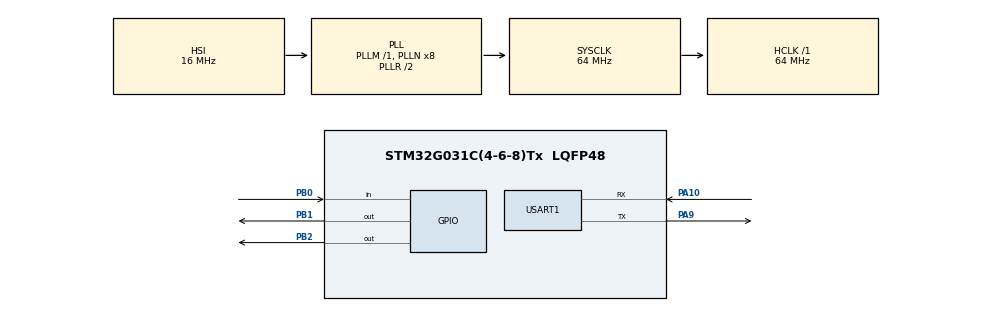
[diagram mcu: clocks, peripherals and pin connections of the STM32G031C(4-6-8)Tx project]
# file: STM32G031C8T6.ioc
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Mcu.Family=STM32G0
Mcu.Name=STM32G031C(4-6-8)Tx
Mcu.Package=LQFP48
PA10.Mode=Asynchronous
PA10.Signal=USART1_RX
PA13.Mode=Serial_Wire
PA13.Signal=SYS_SWDIO
PA14-BOOT0.Mode=Serial_Wire
PA14-BOOT0.Signal=SYS_SWCLK
PA9.Mode=Asynchronous
PA9.Signal=USART1_TX
PB0.Signal=GPIO_Input
PB1.GPIO_ModeDefaultOutputPP=GPIO_MODE_OUTPUT_PP
PB1.PinState=GPIO_PIN_RESET
PB1.Signal=GPIO_Output
PB2.PinState=GPIO_PIN_RESET
PB2.Signal=GPIO_Output
PF0-OSC_IN\ (PF0).Mode=HSE-External-Oscillator
PF0-OSC_IN\ (PF0).Signal=RCC_OSC_IN
PF1-OSC_OUT\ (PF1).Mode=HSE-External-Oscillator
PF1-OSC_OUT\ (PF1).Signal=RCC_OSC_OUT
ProjectManager.HeapSize=0x200
ProjectManager.StackSize=0x400
ProjectManager.TargetToolchain=MDK-ARM V5.32
RCC.ADCFreq_Value=64000000
RCC.AHBFreq_Value=64000000
RCC.CortexFreq_Value=64000000
RCC.EXTERNAL_CLOCK_VALUE=12288000
RCC.HCLKFreq_Value=64000000
RCC.HSE_VALUE=8000000
RCC.HSI_VALUE=16000000
RCC.LSE_VALUE=32768
RCC.SYSCLKFreq_VALUE=64000000
RCC.SYSCLKSource=RCC_SYSCLKSOURCE_PLLCLK
RCC.VCOOutputFreq_Value=128000000
USART1.VirtualMode-Asynchronous=VM_ASYNC
board=custom

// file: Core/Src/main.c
/* USER CODE BEGIN Header */
/**
  ******************************************************************************
  * @file           : main.c
  * @brief          : Main program body
  ******************************************************************************
  * @attention
  *
  * Copyright (c) 2026 STMicroelectronics.
  * All rights reserved.
  *
  * This software is licensed under terms that can be found in the LICENSE file
  * in the root directory of this software component.
  * If no LICENSE file comes with this software, it is provided AS-IS.
  *
  ******************************************************************************
  */
/* USER CODE END Header */
#include "main.h"
#include "usart.h"
#include "gpio.h"

/* USER CODE BEGIN Includes */
#include "ads1232.h"
#include "ads1232_service.h"
#include "weight_processor.h"

/* USER CODE END Includes */

void SystemClock_Config(void);

int main(void)
{

  /* MCU Configuration--------------------------------------------------------*/

  /* Reset of all peripherals, Initializes the Flash interface and the Systick. */
  HAL_Init();

  /* Configure the system clock */
  SystemClock_Config();

  /* Initialize all configured peripherals */
  MX_GPIO_Init();
  MX_USART1_UART_Init();
  /* USER CODE BEGIN 2 */
  (void)ADS1232_Init();
  WeightProcessor_Init();

  /* USER CODE END 2 */

  /* Infinite loop */
  while (1)
  {

    /* USER CODE BEGIN 3 */
    ADS1232_Service10Hz(&huart1);
  }
  /* USER CODE END 3 */
}

void SystemClock_Config(void)
{
  RCC_OscInitTypeDef RCC_OscInitStruct = {0};
  RCC_ClkInitTypeDef RCC_ClkInitStruct = {0};

  /** Configure the main internal regulator output voltage
  */
  HAL_PWREx_ControlVoltageScaling(PWR_REGULATOR_VOLTAGE_SCALE1);

  /** Initializes the RCC Oscillators according to the specified parameters
  * in the RCC_OscInitTypeDef structure.
  */
  RCC_OscInitStruct.OscillatorType = RCC_OSCILLATORTYPE_HSI;
  RCC_OscInitStruct.HSIState = RCC_HSI_ON;
  RCC_OscInitStruct.HSIDiv = RCC_HSI_DIV1;
  RCC_OscInitStruct.HSICalibrationValue = RCC_HSICALIBRATION_DEFAULT;
  RCC_OscInitStruct.PLL.PLLState = RCC_PLL_ON;
  RCC_OscInitStruct.PLL.PLLSource = RCC_PLLSOURCE_HSI;
  RCC_OscInitStruct.PLL.PLLM = RCC_PLLM_DIV1;
  RCC_OscInitStruct.PLL.PLLN = 8;
  RCC_OscInitStruct.PLL.PLLP = RCC_PLLP_DIV2;
  RCC_OscInitStruct.PLL.PLLQ = RCC_PLLQ_DIV2;
  RCC_OscInitStruct.PLL.PLLR = RCC_PLLR_DIV2;
  if (HAL_RCC_OscConfig(&RCC_OscInitStruct) != HAL_OK)
  {
    Error_Handler();
  }

  /** Initializes the CPU, AHB and APB buses clocks
  */
  RCC_ClkInitStruct.ClockType = RCC_CLOCKTYPE_HCLK|RCC_CLOCKTYPE_SYSCLK
                              |RCC_CLOCKTYPE_PCLK1;
  RCC_ClkInitStruct.SYSCLKSource = RCC_SYSCLKSOURCE_PLLCLK;
  RCC_ClkInitStruct.AHBCLKDivider = RCC_SYSCLK_DIV1;
  RCC_ClkInitStruct.APB1CLKDivider = RCC_HCLK_DIV1;

  if (HAL_RCC_ClockConfig(&RCC_ClkInitStruct, FLASH_LATENCY_2) != HAL_OK)
  {
    Error_Handler();
  }
}

void Error_Handler(void)
{
  __disable_irq();
  while (1)
  {
  }
}
